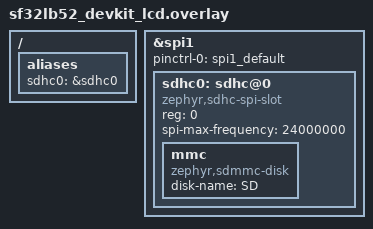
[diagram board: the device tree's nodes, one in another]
/*
 * Copyright (c) 2026 Core Devices LLC
 * Copyright (c) 2026 SiFli Technologies(Nanjing) Co., Ltd
 * SPDX-License-Identifier: Apache-2.0
 */

/ {
	aliases {
		sdhc0 = &sdhc0;
	};
};

&spi1 {
	status = "okay";
	pinctrl-0 = <&spi1_default>;
	pinctrl-names = "default";

	sdhc0: sdhc@0 {
		compatible = "zephyr,sdhc-spi-slot";
		reg = <0>;
		status = "okay";
		spi-max-frequency = <24000000>;

		mmc {
			compatible = "zephyr,sdmmc-disk";
			disk-name = "SD";
			status = "okay";
		};
	};
};
